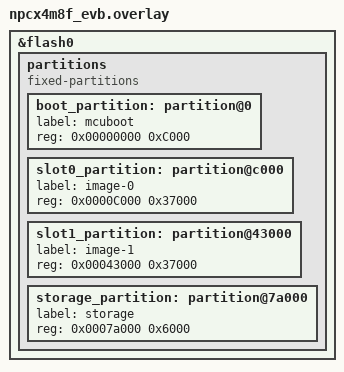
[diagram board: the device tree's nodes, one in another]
&flash0 {
    partitions {
        compatible = "fixed-partitions";
        #address-cells = <1>;
        #size-cells = <1>;

        boot_partition: partition@0 {
            label = "mcuboot";
            reg = <0x00000000 0xC000>;
        };
        slot0_partition: partition@c000 {
            label = "image-0";
            reg = <0x0000C000 0x37000>;
        };
        slot1_partition: partition@43000 {
            label = "image-1";
            reg = <0x00043000 0x37000>;
        };
        storage_partition: partition@7a000 {
            label = "storage";
            reg = <0x0007a000 0x6000>;
        };
    };
};
